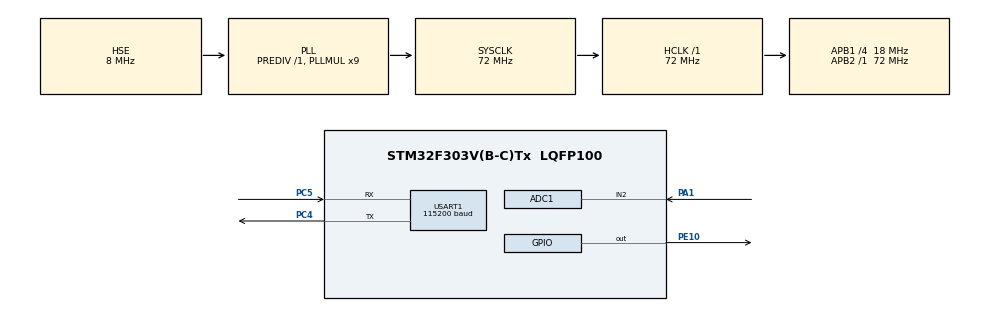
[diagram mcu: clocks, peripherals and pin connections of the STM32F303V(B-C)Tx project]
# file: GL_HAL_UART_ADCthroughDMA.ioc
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ADC1.Channel-1\#ChannelRegularConversion=ADC_CHANNEL_2
ADC1.ContinuousConvMode=ENABLE
ADC1.DMAContinuousRequests=ENABLE
ADC1.NbrOfConversionFlag=1
ADC1.Offset-1\#ChannelRegularConversion=0
ADC1.OffsetNumber-1\#ChannelRegularConversion=ADC_OFFSET_NONE
ADC1.Rank-1\#ChannelRegularConversion=1
ADC1.Resolution=ADC_RESOLUTION_8B
ADC1.SamplingTime-1\#ChannelRegularConversion=ADC_SAMPLETIME_1CYCLE_5
ADC1.master=1
Dma.ADC1.1.Direction=DMA_PERIPH_TO_MEMORY
Dma.ADC1.1.Instance=DMA1_Channel1
Dma.ADC1.1.MemDataAlignment=DMA_MDATAALIGN_BYTE
Dma.ADC1.1.MemInc=DMA_MINC_ENABLE
Dma.ADC1.1.Mode=DMA_CIRCULAR
Dma.ADC1.1.PeriphDataAlignment=DMA_PDATAALIGN_BYTE
Dma.ADC1.1.PeriphInc=DMA_PINC_DISABLE
Dma.ADC1.1.Priority=DMA_PRIORITY_LOW
Dma.Request0=USART1_TX
Dma.Request1=ADC1
Dma.USART1_TX.0.Direction=DMA_MEMORY_TO_PERIPH
Dma.USART1_TX.0.Instance=DMA1_Channel4
Dma.USART1_TX.0.MemDataAlignment=DMA_MDATAALIGN_BYTE
Dma.USART1_TX.0.MemInc=DMA_MINC_ENABLE
Dma.USART1_TX.0.Mode=DMA_NORMAL
Dma.USART1_TX.0.PeriphDataAlignment=DMA_PDATAALIGN_BYTE
Dma.USART1_TX.0.PeriphInc=DMA_PINC_DISABLE
Dma.USART1_TX.0.Priority=DMA_PRIORITY_LOW
Mcu.Family=STM32F3
Mcu.Name=STM32F303V(B-C)Tx
Mcu.Package=LQFP100
NVIC.DMA1_Channel1_IRQn=true\:0\:0\:false\:false\:true\:false\:true
NVIC.DMA1_Channel4_IRQn=true\:0\:0\:false\:false\:true\:false\:true
NVIC.PriorityGroup=NVIC_PRIORITYGROUP_0
NVIC.USART1_IRQn=true\:0\:0\:false\:false\:true\:true\:true
PA1.Mode=IN2-Single-Ended
PA1.Signal=ADC1_IN2
PC4.Mode=Asynchronous
PC4.Signal=USART1_TX
PC5.Mode=Asynchronous
PC5.Signal=USART1_RX
PE10.Signal=GPIO_Output
PF0-OSC_IN.Mode=HSE-External-Oscillator
PF0-OSC_IN.Signal=RCC_OSC_IN
PF1-OSC_OUT.Mode=HSE-External-Oscillator
PF1-OSC_OUT.Signal=RCC_OSC_OUT
ProjectManager.HeapSize=0x200
ProjectManager.StackSize=0x400
ProjectManager.TargetToolchain=MDK-ARM V5.27
RCC.AHBFreq_Value=72000000
RCC.APB1CLKDivider=RCC_HCLK_DIV4
RCC.APB1Freq_Value=18000000
RCC.APB1TimFreq_Value=36000000
RCC.APB2Freq_Value=72000000
RCC.APB2TimFreq_Value=72000000
RCC.CortexFreq_Value=72000000
RCC.HCLKFreq_Value=72000000
RCC.HSE_VALUE=8000000
RCC.HSI_VALUE=8000000
RCC.LSE_VALUE=32768
RCC.PLLMUL=RCC_PLL_MUL9
RCC.PLLSourceVirtual=RCC_PLLSOURCE_HSE
RCC.SYSCLKFreq_VALUE=72000000
RCC.SYSCLKSourceVirtual=RCC_SYSCLKSOURCE_PLLCLK
RCC.USBFreq_Value=72000000
USART1.BaudRate=115200
USART1.VirtualMode-Asynchronous=VM_ASYNC
board=STM32F3DISCOVERY

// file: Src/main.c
/* USER CODE BEGIN Header */
/**
  ******************************************************************************
  * @file           : main.c
  * @brief          : Main program body
  ******************************************************************************
  * @attention
  *
  * <h2><center>&copy; Copyright (c) 2020 STMicroelectronics.
  * All rights reserved.</center></h2>
  *
  * This software component is licensed by ST under BSD 3-Clause license,
  * the "License"; You may not use this file except in compliance with the
  * License. You may obtain a copy of the License at:
  *                        opensource.org/licenses/BSD-3-Clause
  *
  ******************************************************************************
  */
/* USER CODE END Header */

#include "main.h"

/* USER CODE BEGIN PD */
uint8_t buffTx[256];
uint16_t len, i;
/* USER CODE END PD */

ADC_HandleTypeDef hadc1;
DMA_HandleTypeDef hdma_adc1;

UART_HandleTypeDef huart1;
DMA_HandleTypeDef hdma_usart1_tx;

void SystemClock_Config(void);
static void MX_GPIO_Init(void);
static void MX_DMA_Init(void);
static void MX_USART1_UART_Init(void);
static void MX_ADC1_Init(void);

int main(void)
{

  /* MCU Configuration--------------------------------------------------------*/

  /* Reset of all peripherals, Initializes the Flash interface and the Systick. */
  HAL_Init();

  /* Configure the system clock */
  SystemClock_Config();

  /* Initialize all configured peripherals */
  MX_GPIO_Init();
  MX_DMA_Init();
  MX_USART1_UART_Init();
  MX_ADC1_Init();
  /* USER CODE BEGIN 2 */
//for (i=0; i<256; i++) buffTx[i] = i;
len = sizeof(buffTx);
HAL_ADC_Start_DMA(&hadc1, (uint32_t*) buffTx, len);
HAL_UART_Transmit_DMA(&huart1, buffTx, len);
  /* USER CODE END 2 */

  /* Infinite loop */
  while (1)
  {

  }
}

void SystemClock_Config(void)
{
  RCC_OscInitTypeDef RCC_OscInitStruct = {0};
  RCC_ClkInitTypeDef RCC_ClkInitStruct = {0};
  RCC_PeriphCLKInitTypeDef PeriphClkInit = {0};

  /** Initializes the CPU, AHB and APB busses clocks
  */
  RCC_OscInitStruct.OscillatorType = RCC_OSCILLATORTYPE_HSE;
  RCC_OscInitStruct.HSEState = RCC_HSE_ON;
  RCC_OscInitStruct.HSEPredivValue = RCC_HSE_PREDIV_DIV1;
  RCC_OscInitStruct.HSIState = RCC_HSI_ON;
  RCC_OscInitStruct.PLL.PLLState = RCC_PLL_ON;
  RCC_OscInitStruct.PLL.PLLSource = RCC_PLLSOURCE_HSE;
  RCC_OscInitStruct.PLL.PLLMUL = RCC_PLL_MUL9;
  if (HAL_RCC_OscConfig(&RCC_OscInitStruct) != HAL_OK)
  {
    Error_Handler();
  }
  /** Initializes the CPU, AHB and APB busses clocks
  */
  RCC_ClkInitStruct.ClockType = RCC_CLOCKTYPE_HCLK|RCC_CLOCKTYPE_SYSCLK
                              |RCC_CLOCKTYPE_PCLK1|RCC_CLOCKTYPE_PCLK2;
  RCC_ClkInitStruct.SYSCLKSource = RCC_SYSCLKSOURCE_PLLCLK;
  RCC_ClkInitStruct.AHBCLKDivider = RCC_SYSCLK_DIV1;
  RCC_ClkInitStruct.APB1CLKDivider = RCC_HCLK_DIV4;
  RCC_ClkInitStruct.APB2CLKDivider = RCC_HCLK_DIV1;

  if (HAL_RCC_ClockConfig(&RCC_ClkInitStruct, FLASH_LATENCY_2) != HAL_OK)
  {
    Error_Handler();
  }
  PeriphClkInit.PeriphClockSelection = RCC_PERIPHCLK_USART1|RCC_PERIPHCLK_ADC12;
  PeriphClkInit.Usart1ClockSelection = RCC_USART1CLKSOURCE_PCLK2;
  PeriphClkInit.Adc12ClockSelection = RCC_ADC12PLLCLK_DIV1;
  if (HAL_RCCEx_PeriphCLKConfig(&PeriphClkInit) != HAL_OK)
  {
    Error_Handler();
  }
}

static void MX_ADC1_Init(void)
{

  ADC_MultiModeTypeDef multimode = {0};
  ADC_ChannelConfTypeDef sConfig = {0};

  /** Common config
  */
  hadc1.Instance = ADC1;
  hadc1.Init.ClockPrescaler = ADC_CLOCK_ASYNC_DIV1;
  hadc1.Init.Resolution = ADC_RESOLUTION_8B;
  hadc1.Init.ScanConvMode = ADC_SCAN_DISABLE;
  hadc1.Init.ContinuousConvMode = ENABLE;
  hadc1.Init.DiscontinuousConvMode = DISABLE;
  hadc1.Init.ExternalTrigConvEdge = ADC_EXTERNALTRIGCONVEDGE_NONE;
  hadc1.Init.ExternalTrigConv = ADC_SOFTWARE_START;
  hadc1.Init.DataAlign = ADC_DATAALIGN_RIGHT;
  hadc1.Init.NbrOfConversion = 1;
  hadc1.Init.DMAContinuousRequests = ENABLE;
  hadc1.Init.EOCSelection = ADC_EOC_SINGLE_CONV;
  hadc1.Init.LowPowerAutoWait = DISABLE;
  hadc1.Init.Overrun = ADC_OVR_DATA_OVERWRITTEN;
  if (HAL_ADC_Init(&hadc1) != HAL_OK)
  {
    Error_Handler();
  }
  /** Configure the ADC multi-mode
  */
  multimode.Mode = ADC_MODE_INDEPENDENT;
  if (HAL_ADCEx_MultiModeConfigChannel(&hadc1, &multimode) != HAL_OK)
  {
    Error_Handler();
  }
  /** Configure Regular Channel
  */
  sConfig.Channel = ADC_CHANNEL_2;
  sConfig.Rank = ADC_REGULAR_RANK_1;
  sConfig.SingleDiff = ADC_SINGLE_ENDED;
  sConfig.SamplingTime = ADC_SAMPLETIME_1CYCLE_5;
  sConfig.OffsetNumber = ADC_OFFSET_NONE;
  sConfig.Offset = 0;
  if (HAL_ADC_ConfigChannel(&hadc1, &sConfig) != HAL_OK)
  {
    Error_Handler();
  }

}

static void MX_USART1_UART_Init(void)
{

  huart1.Instance = USART1;
  huart1.Init.BaudRate = 115200;
  huart1.Init.WordLength = UART_WORDLENGTH_8B;
  huart1.Init.StopBits = UART_STOPBITS_1;
  huart1.Init.Parity = UART_PARITY_NONE;
  huart1.Init.Mode = UART_MODE_TX_RX;
  huart1.Init.HwFlowCtl = UART_HWCONTROL_NONE;
  huart1.Init.OverSampling = UART_OVERSAMPLING_16;
  huart1.Init.OneBitSampling = UART_ONE_BIT_SAMPLE_DISABLE;
  huart1.AdvancedInit.AdvFeatureInit = UART_ADVFEATURE_NO_INIT;
  if (HAL_UART_Init(&huart1) != HAL_OK)
  {
    Error_Handler();
  }

}

static void MX_DMA_Init(void)
{

  /* DMA controller clock enable */
  __HAL_RCC_DMA1_CLK_ENABLE();

  /* DMA interrupt init */
  /* DMA1_Channel1_IRQn interrupt configuration */
  HAL_NVIC_SetPriority(DMA1_Channel1_IRQn, 0, 0);
  HAL_NVIC_EnableIRQ(DMA1_Channel1_IRQn);
  /* DMA1_Channel4_IRQn interrupt configuration */
  HAL_NVIC_SetPriority(DMA1_Channel4_IRQn, 0, 0);
  HAL_NVIC_EnableIRQ(DMA1_Channel4_IRQn);

}

static void MX_GPIO_Init(void)
{
  GPIO_InitTypeDef GPIO_InitStruct = {0};

  /* GPIO Ports Clock Enable */
  __HAL_RCC_GPIOF_CLK_ENABLE();
  __HAL_RCC_GPIOA_CLK_ENABLE();
  __HAL_RCC_GPIOC_CLK_ENABLE();
  __HAL_RCC_GPIOE_CLK_ENABLE();

  /*Configure GPIO pin Output Level */
  HAL_GPIO_WritePin(GPIOE, GPIO_PIN_10, GPIO_PIN_RESET);

  /*Configure GPIO pin : PE10 */
  GPIO_InitStruct.Pin = GPIO_PIN_10;
  GPIO_InitStruct.Mode = GPIO_MODE_OUTPUT_PP;
  GPIO_InitStruct.Pull = GPIO_NOPULL;
  GPIO_InitStruct.Speed = GPIO_SPEED_FREQ_LOW;
  HAL_GPIO_Init(GPIOE, &GPIO_InitStruct);

}

void Error_Handler(void)
{
}

/************************ (C) COPYRIGHT STMicroelectronics *****END OF FILE****/
